# armv7_pmu register map
Registers are 32-bit, access not given, no defined reset value unless marked. A register's access mark holds for its fields unless they carry their own. Offsets are from the block's base; lines under a group give offsets from that group; [hi:lo] are bit positions; {n}, {i} and the like mark numbered series; 'fields as' and 'values as' point back to an identical list; <NAME> marks a mode.

## Memory map
? PMU%s size 0x1000

## PMU%s
Base ?
{0x0+4i} PMXEVCNTR{i} (i=0..31)
  [31:0] PMN
0x7C PMCCNTR
  [31:0] CCNT
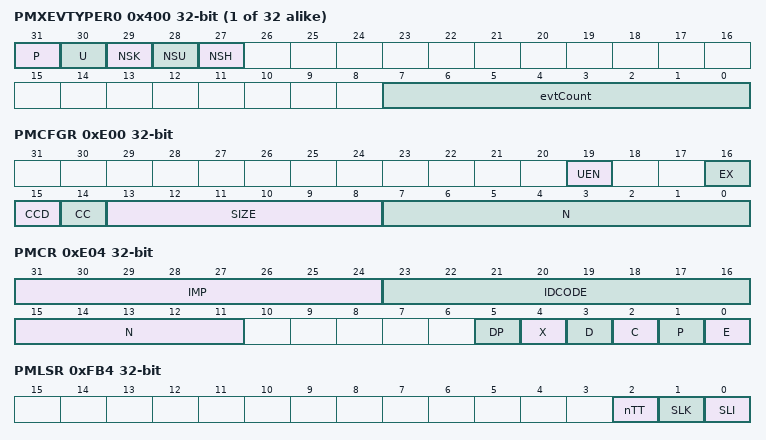
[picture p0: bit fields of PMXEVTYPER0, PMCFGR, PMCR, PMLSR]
{0x400+4i} PMXEVTYPER{i} (i=0..31)
  [31] P, [30] U, [29] NSK, [28] NSU, [27] NSH, [7:0] evtCount
0xC00 PMCNTENSET
  [31] C, [n] P{n} (n=0..31)
0xC20 PMCNTENCLR
  [31] C, [n] P{n} (n=0..31)
0xC40 PMINTENSET
  [31] C, [n] P{n} (n=0..31)
0xC60 PMINTENCLR
  [31] C, [n] P{n} (n=0..31)
0xC80 PMOVSR
  [31] C, [n] P{n} (n=0..31)
0xCA0 PMSWINC
  [31] C, [n] P{n} (n=0..31)
0xCC0 PMOVSSET
  [31] C, [n] P{n} (n=0..31)
0xE00 PMCFGR
  [19] UEN, [16] EX, [15] CCD, [14] CC, [13:8] SIZE, [7:0] N
0xE04 PMCR
  [31:24] IMP, [23:16] IDCODE, [15:11] N, [5] DP, [4] X, [3] D, [2] C, [1] P, [0] E
0xE08 PMUSERENR
  [0] EN
0xE20 PMCEID0
0xE24 PMCEID1
0xFB0 PMLAR
0xFB4 PMLSR
  [2] nTT, [1] SLK, [0] SLI
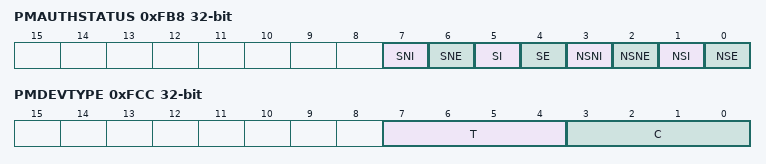
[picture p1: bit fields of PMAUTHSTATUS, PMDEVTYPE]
0xFB8 PMAUTHSTATUS
  [7] SNI, [6] SNE, [5] SI, [4] SE, [3] NSNI, [2] NSNE, [1] NSI, [0] NSE
0xFCC PMDEVTYPE
  [7:4] T, [3:0] C
